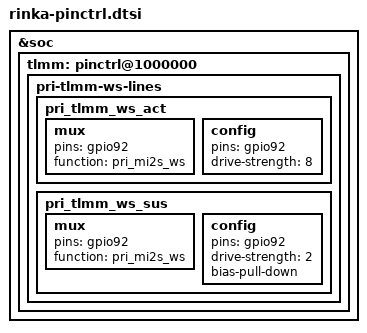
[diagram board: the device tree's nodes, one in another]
&soc {
	tlmm: pinctrl@1000000 {

		pri-tlmm-ws-lines {

			pri_tlmm_ws_act: pri_tlmm_ws_act {
				mux {
					pins = "gpio92";
					function = "pri_mi2s_ws";
				};

				config {
					pins = "gpio92";
					drive-strength = <8>;
				};
			};

			pri_tlmm_ws_sus: pri_tlmm_ws_sus {
				mux {
					pins = "gpio92";
					function = "pri_mi2s_ws";
				};

				config {
					pins = "gpio92";
					drive-strength = <2>;
					bias-pull-down;
				};
			};
		};
	};
};
